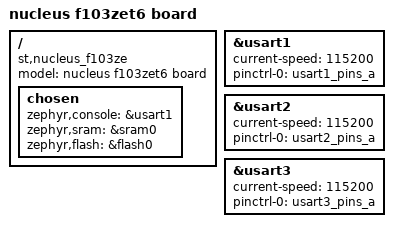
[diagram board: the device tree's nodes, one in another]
/*
 * Copyright (c) 2017 Linaro Limited
 *
 * SPDX-License-Identifier: Apache-2.0
 */

/dts-v1/;
#include <st/stm32f103Xe.dtsi>

/ {
	model = "nucleus f103zet6 board";
	compatible = "st,nucleus_f103ze", "st,stm32f103ve";

	chosen {
		zephyr,console = &usart1;
		zephyr,sram = &sram0;
		zephyr,flash = &flash0;
	};
};

&usart1 {
	current-speed = <115200>;
	pinctrl-0 = <&usart1_pins_a>;
	pinctrl-names = "default";
	status = "ok";
};

&usart2 {
	current-speed = <115200>;
	pinctrl-0 = <&usart2_pins_a>;
	pinctrl-names = "default";
	status = "ok";
};

&usart3 {
	current-speed = <115200>;
	pinctrl-0 = <&usart3_pins_a>;
	pinctrl-names = "default";
};
